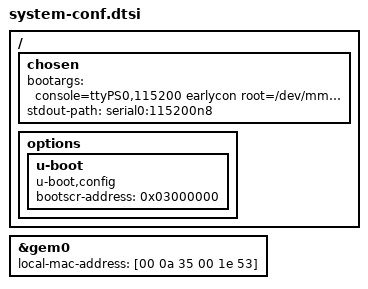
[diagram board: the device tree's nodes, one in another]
/*
 * CAUTION: This file is automatically generated by PetaLinux SDK.
 * DO NOT modify this file
 */


/ {
	chosen {
		bootargs = "console=ttyPS0,115200 earlycon root=/dev/mmcblk0p2 ro rootwait";
		stdout-path = "serial0:115200n8";
	};

	options {
		u-boot {
			compatible = "u-boot,config";
			bootscr-address = /bits/ 64 <0x03000000>;
		};
	};
};

&gem0 {
	local-mac-address = [00 0a 35 00 1e 53];
};

